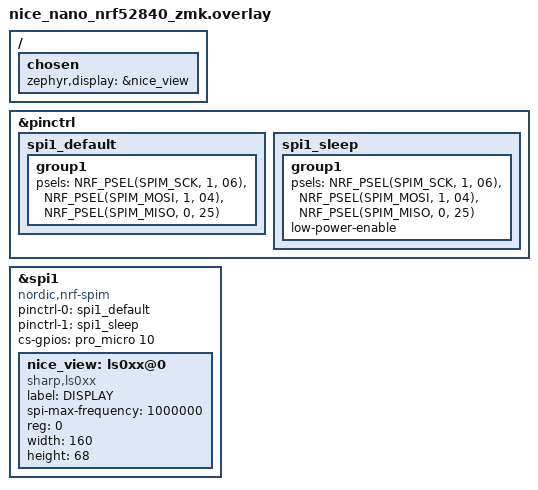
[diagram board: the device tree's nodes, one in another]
/*
 * Copyright (c) 2024 Curtis Bollinger
 *
 * SPDX-License-Identifier: MIT
 */


/*
 * Curtis originally defined spi0, but this conflicts with the i2c0
 * used for the trackpad. To make it a little easier to switch between the two
 * we will switch the display to spi1 and override the pin defaults in
 * zmkfirmware/zmk/app/module/boards/nicekeyboards/nice_nano/nice_nano-pinctrl.dtsi
 */


&pinctrl {
    spi1_default: spi1_default {
        group1 {
            psels = <NRF_PSEL(SPIM_SCK, 1, 06)>,  // P1.06
                    <NRF_PSEL(SPIM_MOSI, 1, 04)>, // P1.04
                    <NRF_PSEL(SPIM_MISO, 0, 25)>;
        };
    };
    spi1_sleep: spi1_sleep {
        group1 {
            psels = <NRF_PSEL(SPIM_SCK, 1, 06)>,
                    <NRF_PSEL(SPIM_MOSI, 1, 04)>,
                    <NRF_PSEL(SPIM_MISO, 0, 25)>;
            low-power-enable;
        };
    };
};

nice_view_spi: &spi1 {
    compatible = "nordic,nrf-spim";
    pinctrl-0 = <&spi1_default>;
    pinctrl-1 = <&spi1_sleep>;
    pinctrl-names = "default", "sleep";
    cs-gpios = <&pro_micro 10 GPIO_ACTIVE_HIGH>; // P0.09
    status = "okay";

    nice_view: ls0xx@0 {
        compatible = "sharp,ls0xx";
        label = "DISPLAY";
        spi-max-frequency = <1000000>;
        reg = <0>;
        width = <160>;
        height = <68>;
    };
};

/ {
    chosen {
        zephyr,display = &nice_view;
    };
};
